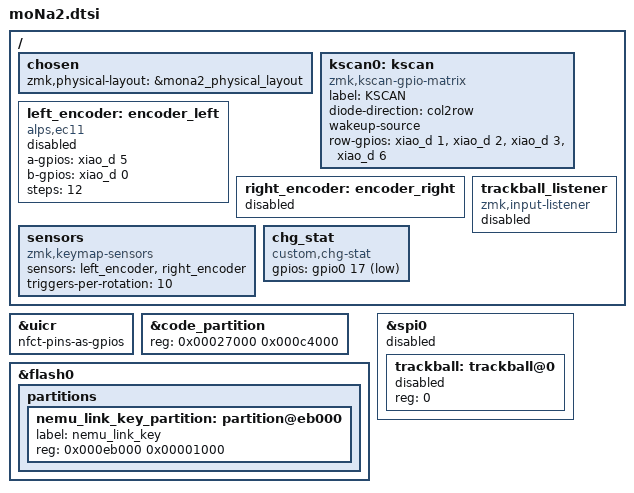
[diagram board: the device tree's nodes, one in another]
#include "moNa2-layouts.dtsi"
#include "../../../config/nemu-link.dtsi"

&uicr {
    nfct-pins-as-gpios;
};

/* Reserve the last application page without moving Settings or the UF2 bootloader. */
&code_partition {
    reg = <0x00027000 0x000c4000>;
};

&flash0 {
    partitions {
        nemu_link_key_partition: partition@eb000 {
            label = "nemu_link_key";
            reg = <0x000eb000 0x00001000>;
        };
    };
};

/ {
    chosen {
        zmk,physical-layout = &mona2_physical_layout;
    };


    kscan0: kscan {
        compatible = "zmk,kscan-gpio-matrix";
        label = "KSCAN";
        diode-direction = "col2row";
        wakeup-source;
            row-gpios
                = <&xiao_d 1 (GPIO_ACTIVE_HIGH | GPIO_PULL_DOWN)>
                , <&xiao_d 2 (GPIO_ACTIVE_HIGH | GPIO_PULL_DOWN)>
                , <&xiao_d 3 (GPIO_ACTIVE_HIGH | GPIO_PULL_DOWN)>
                , <&xiao_d 6 (GPIO_ACTIVE_HIGH | GPIO_PULL_DOWN)>
                ;
    };

    left_encoder: encoder_left {
        compatible = "alps,ec11";
        a-gpios = <&xiao_d 5 (GPIO_ACTIVE_HIGH | GPIO_PULL_UP)>;
        b-gpios = <&xiao_d 0 (GPIO_ACTIVE_HIGH | GPIO_PULL_UP)>;
        steps = <12>;
        status = "disabled";
    };

    right_encoder: encoder_right {
        status = "disabled";
    };

    sensors: sensors {
        compatible = "zmk,keymap-sensors";
        sensors = <&left_encoder &right_encoder>;
        triggers-per-rotation = <10>;
    };

    trackball_listener: trackball_listener {
        compatible = "zmk,input-listener";
        status = "disabled";
    };
};

&spi0 {
    status = "disabled";

    trackball: trackball@0 {
        status = "disabled";
        reg = <0>;
    };
};

/ {
    chg_stat: chg_stat {
        compatible = "custom,chg-stat";
        status = "okay";
        gpios = <&gpio0 17 GPIO_ACTIVE_LOW>;
    };
};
